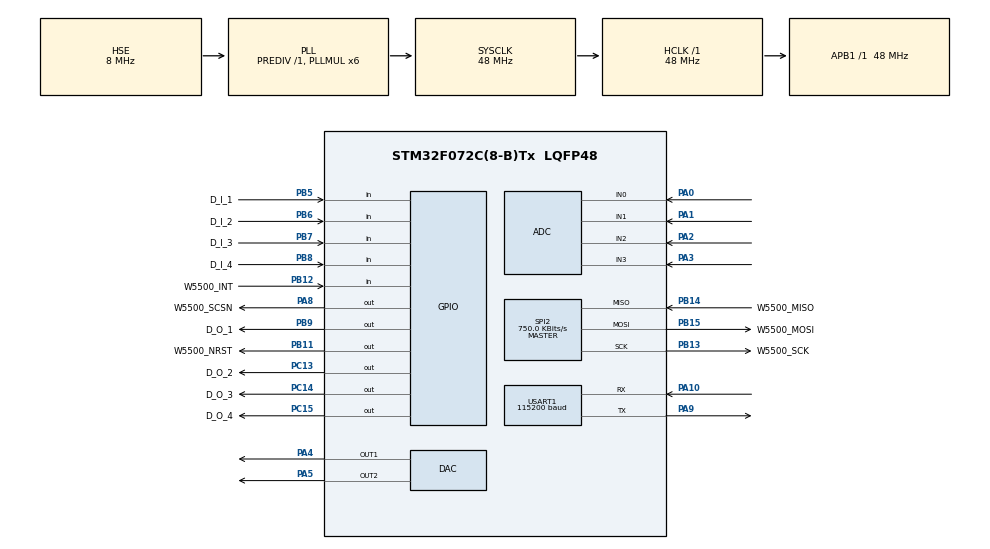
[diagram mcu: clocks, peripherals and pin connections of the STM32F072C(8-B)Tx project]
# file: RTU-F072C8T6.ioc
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ADC.ClockPrescaler=ADC_CLOCK_ASYNC_DIV1
ADC.ContinuousConvMode=ENABLE
ADC.DMAContinuousRequests=ENABLE
ADC.EOCSelection=ADC_EOC_SEQ_CONV
ADC.Overrun=ADC_OVR_DATA_PRESERVED
ADC.SamplingTime=ADC_SAMPLETIME_41CYCLES_5
Dma.ADC.0.Direction=DMA_PERIPH_TO_MEMORY
Dma.ADC.0.Instance=DMA1_Channel1
Dma.ADC.0.MemDataAlignment=DMA_MDATAALIGN_HALFWORD
Dma.ADC.0.MemInc=DMA_MINC_ENABLE
Dma.ADC.0.Mode=DMA_CIRCULAR
Dma.ADC.0.PeriphDataAlignment=DMA_PDATAALIGN_HALFWORD
Dma.ADC.0.PeriphInc=DMA_PINC_DISABLE
Dma.ADC.0.Priority=DMA_PRIORITY_LOW
Dma.Request0=ADC
Mcu.Family=STM32F0
Mcu.Name=STM32F072C(8-B)Tx
Mcu.Package=LQFP48
NVIC.DMA1_Channel1_IRQn=true\:0\:0\:false\:false\:true\:false\:true
NVIC.USART1_IRQn=true\:0\:0\:false\:false\:true\:true\:true
PA0.Mode=IN0
PA0.Signal=ADC_IN0
PA1.Mode=IN1
PA1.Signal=ADC_IN1
PA10.Mode=Asynchronous
PA10.Signal=USART1_RX
PA13.Mode=Serial_Wire
PA13.Signal=SYS_SWDIO
PA14.Mode=Serial_Wire
PA14.Signal=SYS_SWCLK
PA2.Mode=IN2
PA2.Signal=ADC_IN2
PA3.Mode=IN3
PA3.Signal=ADC_IN3
PA4.Signal=COMP_DAC1_group
PA5.Signal=COMP_DAC2_group
PA8.GPIO_Label=W5500_SCSN
PA8.Signal=GPIO_Output
PA9.Mode=Asynchronous
PA9.Signal=USART1_TX
PB11.GPIO_Label=W5500_NRST
PB11.GPIO_PuPd=GPIO_NOPULL
PB11.PinState=GPIO_PIN_RESET
PB11.Signal=GPIO_Output
PB12.GPIO_Label=W5500_INT
PB12.Signal=GPIO_Input
PB13.GPIO_Label=W5500_SCK
PB13.Mode=Full_Duplex_Master
PB13.Signal=SPI2_SCK
PB14.GPIO_Label=W5500_MISO
PB14.Mode=Full_Duplex_Master
PB14.Signal=SPI2_MISO
PB15.GPIO_Label=W5500_MOSI
PB15.Mode=Full_Duplex_Master
PB15.Signal=SPI2_MOSI
PB5.GPIO_Label=D_I_1
PB5.Signal=GPIO_Input
PB6.GPIO_Label=D_I_2
PB6.Signal=GPIO_Input
PB7.GPIO_Label=D_I_3
PB7.Signal=GPIO_Input
PB8.GPIO_Label=D_I_4
PB8.Signal=GPIO_Input
PB9.GPIO_Label=D_O_1
PB9.Signal=GPIO_Output
PC13.GPIO_Label=D_O_2
PC13.Signal=GPIO_Output
PC14-OSC32_IN.GPIO_Label=D_O_3
PC14-OSC32_IN.Signal=GPIO_Output
PC15-OSC32_OUT.GPIO_Label=D_O_4
PC15-OSC32_OUT.Signal=GPIO_Output
PF0-OSC_IN.Mode=HSE-External-Oscillator
PF0-OSC_IN.Signal=RCC_OSC_IN
PF1-OSC_OUT.Mode=HSE-External-Oscillator
PF1-OSC_OUT.Signal=RCC_OSC_OUT
ProjectManager.HeapSize=0x200
ProjectManager.StackSize=0x400
ProjectManager.TargetToolchain=STM32CubeIDE
RCC.AHBFreq_Value=48000000
RCC.APB1Freq_Value=48000000
RCC.APB1TimFreq_Value=48000000
RCC.HCLKFreq_Value=48000000
RCC.PLLMUL=RCC_PLL_MUL6
RCC.PLLSourceVirtual=RCC_PLLSOURCE_HSE
RCC.SYSCLKFreq_VALUE=48000000
RCC.SYSCLKSource=RCC_SYSCLKSOURCE_PLLCLK
SH.COMP_DAC1_group.0=DAC_OUT1,DAC_OUT1
SH.COMP_DAC2_group.0=DAC_OUT2,DAC_OUT2
SPI2.BaudRatePrescaler=SPI_BAUDRATEPRESCALER_64
SPI2.CalculateBaudRate=750.0 KBits/s
SPI2.DataSize=SPI_DATASIZE_8BIT
SPI2.Direction=SPI_DIRECTION_2LINES
SPI2.Mode=SPI_MODE_MASTER
SPI2.VirtualType=VM_MASTER
USART1.BaudRate=115200
USART1.VirtualMode-Asynchronous=VM_ASYNC
board=custom

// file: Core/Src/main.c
/* USER CODE BEGIN Header */
/**
  ******************************************************************************
  * @file           : main.c
  * @brief          : Main program body
  ******************************************************************************
  * @attention
  *
  * Copyright (c) 2022 STMicroelectronics.
  * All rights reserved.
  *
  * This software is licensed under terms that can be found in the LICENSE file
  * in the root directory of this software component.
  * If no LICENSE file comes with this software, it is provided AS-IS.
  *
  ******************************************************************************
  */
/* USER CODE END Header */
#include "main.h"

ADC_HandleTypeDef hadc;
DMA_HandleTypeDef hdma_adc;

DAC_HandleTypeDef hdac;

SPI_HandleTypeDef hspi2;

UART_HandleTypeDef huart1;

void SystemClock_Config(void);
static void MX_GPIO_Init(void);
static void MX_ADC_Init(void);
static void MX_DAC_Init(void);
static void MX_SPI2_Init(void);
static void MX_DMA_Init(void);
static void MX_USART1_UART_Init(void);

int main(void)
{

  /* MCU Configuration--------------------------------------------------------*/

  /* Reset of all peripherals, Initializes the Flash interface and the Systick. */
  HAL_Init();

  /* Configure the system clock */
  SystemClock_Config();

  /* Initialize all configured peripherals */
  MX_GPIO_Init();
  MX_ADC_Init();
  MX_DAC_Init();
  MX_SPI2_Init();
  MX_DMA_Init();
  MX_USART1_UART_Init();
  /* USER CODE BEGIN 2 */

  Task();

  /* USER CODE END 2 */

  /* Infinite loop */
  while (1)
  {

  }
}

void SystemClock_Config(void)
{
  RCC_OscInitTypeDef RCC_OscInitStruct = {0};
  RCC_ClkInitTypeDef RCC_ClkInitStruct = {0};
  RCC_PeriphCLKInitTypeDef PeriphClkInit = {0};

  /** Initializes the RCC Oscillators according to the specified parameters
  * in the RCC_OscInitTypeDef structure.
  */
  RCC_OscInitStruct.OscillatorType = RCC_OSCILLATORTYPE_HSI14|RCC_OSCILLATORTYPE_HSE;
  RCC_OscInitStruct.HSEState = RCC_HSE_ON;
  RCC_OscInitStruct.HSI14State = RCC_HSI14_ON;
  RCC_OscInitStruct.HSI14CalibrationValue = 16;
  RCC_OscInitStruct.PLL.PLLState = RCC_PLL_ON;
  RCC_OscInitStruct.PLL.PLLSource = RCC_PLLSOURCE_HSE;
  RCC_OscInitStruct.PLL.PLLMUL = RCC_PLL_MUL6;
  RCC_OscInitStruct.PLL.PREDIV = RCC_PREDIV_DIV1;
  if (HAL_RCC_OscConfig(&RCC_OscInitStruct) != HAL_OK)
  {
    Error_Handler();
  }
  /** Initializes the CPU, AHB and APB buses clocks
  */
  RCC_ClkInitStruct.ClockType = RCC_CLOCKTYPE_HCLK|RCC_CLOCKTYPE_SYSCLK
                              |RCC_CLOCKTYPE_PCLK1;
  RCC_ClkInitStruct.SYSCLKSource = RCC_SYSCLKSOURCE_PLLCLK;
  RCC_ClkInitStruct.AHBCLKDivider = RCC_SYSCLK_DIV1;
  RCC_ClkInitStruct.APB1CLKDivider = RCC_HCLK_DIV1;

  if (HAL_RCC_ClockConfig(&RCC_ClkInitStruct, FLASH_LATENCY_1) != HAL_OK)
  {
    Error_Handler();
  }
  PeriphClkInit.PeriphClockSelection = RCC_PERIPHCLK_USART1;
  PeriphClkInit.Usart1ClockSelection = RCC_USART1CLKSOURCE_PCLK1;
  if (HAL_RCCEx_PeriphCLKConfig(&PeriphClkInit) != HAL_OK)
  {
    Error_Handler();
  }
}

static void MX_ADC_Init(void)
{

  ADC_ChannelConfTypeDef sConfig = {0};

  /** Configure the global features of the ADC (Clock, Resolution, Data Alignment and number of conversion)
  */
  hadc.Instance = ADC1;
  hadc.Init.ClockPrescaler = ADC_CLOCK_ASYNC_DIV1;
  hadc.Init.Resolution = ADC_RESOLUTION_12B;
  hadc.Init.DataAlign = ADC_DATAALIGN_RIGHT;
  hadc.Init.ScanConvMode = ADC_SCAN_DIRECTION_FORWARD;
  hadc.Init.EOCSelection = ADC_EOC_SEQ_CONV;
  hadc.Init.LowPowerAutoWait = DISABLE;
  hadc.Init.LowPowerAutoPowerOff = DISABLE;
  hadc.Init.ContinuousConvMode = ENABLE;
  hadc.Init.DiscontinuousConvMode = DISABLE;
  hadc.Init.ExternalTrigConv = ADC_SOFTWARE_START;
  hadc.Init.ExternalTrigConvEdge = ADC_EXTERNALTRIGCONVEDGE_NONE;
  hadc.Init.DMAContinuousRequests = ENABLE;
  hadc.Init.Overrun = ADC_OVR_DATA_PRESERVED;
  if (HAL_ADC_Init(&hadc) != HAL_OK)
  {
    Error_Handler();
  }
  /** Configure for the selected ADC regular channel to be converted.
  */
  sConfig.Channel = ADC_CHANNEL_0;
  sConfig.Rank = ADC_RANK_CHANNEL_NUMBER;
  sConfig.SamplingTime = ADC_SAMPLETIME_41CYCLES_5;
  if (HAL_ADC_ConfigChannel(&hadc, &sConfig) != HAL_OK)
  {
    Error_Handler();
  }
  /** Configure for the selected ADC regular channel to be converted.
  */
  sConfig.Channel = ADC_CHANNEL_1;
  if (HAL_ADC_ConfigChannel(&hadc, &sConfig) != HAL_OK)
  {
    Error_Handler();
  }
  /** Configure for the selected ADC regular channel to be converted.
  */
  sConfig.Channel = ADC_CHANNEL_2;
  if (HAL_ADC_ConfigChannel(&hadc, &sConfig) != HAL_OK)
  {
    Error_Handler();
  }
  /** Configure for the selected ADC regular channel to be converted.
  */
  sConfig.Channel = ADC_CHANNEL_3;
  if (HAL_ADC_ConfigChannel(&hadc, &sConfig) != HAL_OK)
  {
    Error_Handler();
  }

}

static void MX_DAC_Init(void)
{

  DAC_ChannelConfTypeDef sConfig = {0};

  /** DAC Initialization
  */
  hdac.Instance = DAC;
  if (HAL_DAC_Init(&hdac) != HAL_OK)
  {
    Error_Handler();
  }
  /** DAC channel OUT1 config
  */
  sConfig.DAC_Trigger = DAC_TRIGGER_NONE;
  sConfig.DAC_OutputBuffer = DAC_OUTPUTBUFFER_ENABLE;
  if (HAL_DAC_ConfigChannel(&hdac, &sConfig, DAC_CHANNEL_1) != HAL_OK)
  {
    Error_Handler();
  }
  /** DAC channel OUT2 config
  */
  if (HAL_DAC_ConfigChannel(&hdac, &sConfig, DAC_CHANNEL_2) != HAL_OK)
  {
    Error_Handler();
  }

}

static void MX_SPI2_Init(void)
{

  /* SPI2 parameter configuration*/
  hspi2.Instance = SPI2;
  hspi2.Init.Mode = SPI_MODE_MASTER;
  hspi2.Init.Direction = SPI_DIRECTION_2LINES;
  hspi2.Init.DataSize = SPI_DATASIZE_8BIT;
  hspi2.Init.CLKPolarity = SPI_POLARITY_LOW;
  hspi2.Init.CLKPhase = SPI_PHASE_1EDGE;
  hspi2.Init.NSS = SPI_NSS_SOFT;
  hspi2.Init.BaudRatePrescaler = SPI_BAUDRATEPRESCALER_64;
  hspi2.Init.FirstBit = SPI_FIRSTBIT_MSB;
  hspi2.Init.TIMode = SPI_TIMODE_DISABLE;
  hspi2.Init.CRCCalculation = SPI_CRCCALCULATION_DISABLE;
  hspi2.Init.CRCPolynomial = 7;
  hspi2.Init.CRCLength = SPI_CRC_LENGTH_DATASIZE;
  hspi2.Init.NSSPMode = SPI_NSS_PULSE_ENABLE;
  if (HAL_SPI_Init(&hspi2) != HAL_OK)
  {
    Error_Handler();
  }

}

static void MX_USART1_UART_Init(void)
{

  huart1.Instance = USART1;
  huart1.Init.BaudRate = 115200;
  huart1.Init.WordLength = UART_WORDLENGTH_8B;
  huart1.Init.StopBits = UART_STOPBITS_1;
  huart1.Init.Parity = UART_PARITY_NONE;
  huart1.Init.Mode = UART_MODE_TX_RX;
  huart1.Init.HwFlowCtl = UART_HWCONTROL_NONE;
  huart1.Init.OverSampling = UART_OVERSAMPLING_16;
  huart1.Init.OneBitSampling = UART_ONE_BIT_SAMPLE_DISABLE;
  huart1.AdvancedInit.AdvFeatureInit = UART_ADVFEATURE_NO_INIT;
  if (HAL_UART_Init(&huart1) != HAL_OK)
  {
    Error_Handler();
  }

}

static void MX_DMA_Init(void)
{

  /* DMA controller clock enable */
  __HAL_RCC_DMA1_CLK_ENABLE();

  /* DMA interrupt init */
  /* DMA1_Channel1_IRQn interrupt configuration */
  HAL_NVIC_SetPriority(DMA1_Channel1_IRQn, 0, 0);
  HAL_NVIC_EnableIRQ(DMA1_Channel1_IRQn);

}

static void MX_GPIO_Init(void)
{
  GPIO_InitTypeDef GPIO_InitStruct = {0};

  /* GPIO Ports Clock Enable */
  __HAL_RCC_GPIOC_CLK_ENABLE();
  __HAL_RCC_GPIOF_CLK_ENABLE();
  __HAL_RCC_GPIOA_CLK_ENABLE();
  __HAL_RCC_GPIOB_CLK_ENABLE();

  /*Configure GPIO pin Output Level */
  HAL_GPIO_WritePin(GPIOC, D_O_2_Pin|D_O_3_Pin|D_O_4_Pin, GPIO_PIN_RESET);

  /*Configure GPIO pin Output Level */
  HAL_GPIO_WritePin(GPIOB, W5500_NRST_Pin|D_O_1_Pin, GPIO_PIN_RESET);

  /*Configure GPIO pin Output Level */
  HAL_GPIO_WritePin(W5500_SCSN_GPIO_Port, W5500_SCSN_Pin, GPIO_PIN_RESET);

  /*Configure GPIO pins : D_O_2_Pin D_O_3_Pin D_O_4_Pin */
  GPIO_InitStruct.Pin = D_O_2_Pin|D_O_3_Pin|D_O_4_Pin;
  GPIO_InitStruct.Mode = GPIO_MODE_OUTPUT_PP;
  GPIO_InitStruct.Pull = GPIO_NOPULL;
  GPIO_InitStruct.Speed = GPIO_SPEED_FREQ_LOW;
  HAL_GPIO_Init(GPIOC, &GPIO_InitStruct);

  /*Configure GPIO pins : W5500_NRST_Pin D_O_1_Pin */
  GPIO_InitStruct.Pin = W5500_NRST_Pin|D_O_1_Pin;
  GPIO_InitStruct.Mode = GPIO_MODE_OUTPUT_PP;
  GPIO_InitStruct.Pull = GPIO_NOPULL;
  GPIO_InitStruct.Speed = GPIO_SPEED_FREQ_LOW;
  HAL_GPIO_Init(GPIOB, &GPIO_InitStruct);

  /*Configure GPIO pins : W5500_INT_Pin D_I_1_Pin D_I_2_Pin D_I_3_Pin
                           D_I_4_Pin */
  GPIO_InitStruct.Pin = W5500_INT_Pin|D_I_1_Pin|D_I_2_Pin|D_I_3_Pin
                          |D_I_4_Pin;
  GPIO_InitStruct.Mode = GPIO_MODE_INPUT;
  GPIO_InitStruct.Pull = GPIO_NOPULL;
  HAL_GPIO_Init(GPIOB, &GPIO_InitStruct);

  /*Configure GPIO pin : W5500_SCSN_Pin */
  GPIO_InitStruct.Pin = W5500_SCSN_Pin;
  GPIO_InitStruct.Mode = GPIO_MODE_OUTPUT_PP;
  GPIO_InitStruct.Pull = GPIO_NOPULL;
  GPIO_InitStruct.Speed = GPIO_SPEED_FREQ_LOW;
  HAL_GPIO_Init(W5500_SCSN_GPIO_Port, &GPIO_InitStruct);

}

void Error_Handler(void)
{
  __disable_irq();
  while (1)
  {
  }
}
